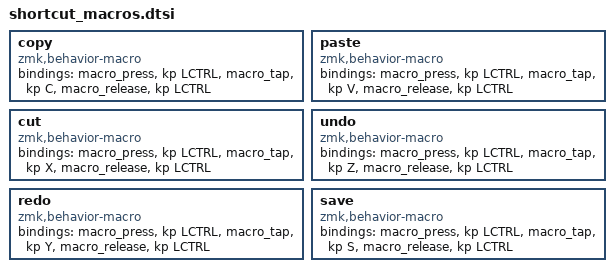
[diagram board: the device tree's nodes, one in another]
    copy: copy {
        compatible = "zmk,behavior-macro";
        #binding-cells = <0>;
        
        bindings
            = <&macro_press   &kp LCTRL>
            , <&macro_tap     &kp C>
            , <&macro_release &kp LCTRL>
        ;
    };

    paste: paste {
        compatible = "zmk,behavior-macro";
        #binding-cells = <0>;
        
        bindings
            = <&macro_press   &kp LCTRL>
            , <&macro_tap     &kp V>
            , <&macro_release &kp LCTRL>
        ;
    };

    cut: cut {
        compatible = "zmk,behavior-macro";
        #binding-cells = <0>;
        
        bindings
            = <&macro_press   &kp LCTRL>
            , <&macro_tap     &kp X>
            , <&macro_release &kp LCTRL>
        ;
    };

    undo: undo {
        compatible = "zmk,behavior-macro";
        #binding-cells = <0>;
        
        bindings
            = <&macro_press   &kp LCTRL>
            , <&macro_tap     &kp Z>
            , <&macro_release &kp LCTRL>
        ;
    };

    redo: redo {
        compatible = "zmk,behavior-macro";
        #binding-cells = <0>;
        
        bindings
            = <&macro_press   &kp LCTRL>
            , <&macro_tap     &kp Y>
            , <&macro_release &kp LCTRL>
        ;
    };

    save: save {
        compatible = "zmk,behavior-macro";
        #binding-cells = <0>;
        
        bindings
            = <&macro_press   &kp LCTRL>
            , <&macro_tap     &kp S>
            , <&macro_release &kp LCTRL>
        ;
    };
